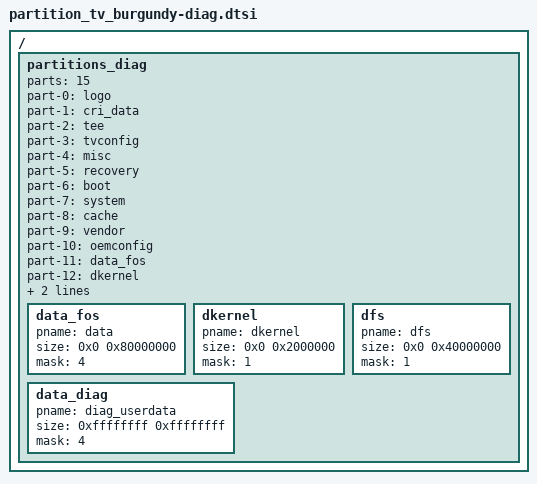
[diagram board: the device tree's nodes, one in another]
/*
 * Amlogic partition set for normal
 *
 * Copyright (c) 2017-2017 Amlogic Ltd
 *
 * This file is licensed under a dual GPLv2 or BSD license.
 *
 */
 / {
    partitions_diag: partitions_diag{
        parts = <15>;
		part-0 = <&logo>;
		part-1 = <&cri_data>;
		part-2 = <&tee>;
		part-3 = <&tvconfig>;
		part-4 = <&misc>;
		part-5 = <&recovery>;
		part-6 = <&boot>;
		part-7 = <&system>;
		part-8 = <&cache>;
		part-9 = <&vendor>;
		part-10 = <&oemconfig>;
		part-11 = <&data_fos>;
		part-12 = <&dkernel>;
		part-13 = <&dfs>;
		part-14 = <&data_diag>;

		data_fos:data_fos
		{
			pname = "data";
			size = <0x0 0x80000000>;
			mask = <4>;
		};
		dkernel:dkernel
		{
			pname = "dkernel";
			size = <0x0 0x2000000>;
			mask = <1>;
		};
		dfs:dfs
		{
			pname = "dfs";
			size = <0x0 0x40000000>;
			mask = <1>;
		};
		data_diag:data_diag
		{
			pname = "diag_userdata";
			size = <0xffffffff 0xffffffff>;
			mask = <4>;
		};
	};
 };/* end of / */
